VERSION ""

NS_ :

BS_:

BU_: ACU VCU
VAL_TABLE_ GEAR_FAULT 1 "GEAR_FAULT" 0 "GEAR_NO_FAULT" ;
VAL_TABLE_ GEAR_Act 2 "GEAR_ACTUAL_REVERSE" 1 "GEAR_ACTUAL_DRIVE" 0 "GEAR_ACTUAL_NEUTRAL" ;
VAL_TABLE_ GEAR_TARGET 2 "GEAR_TARGET_REVERSE" 1 "GEAR_TARGET_DRIVE" 0 "GEAR_TARGET_NEUTRAL" ;
VAL_TABLE_ GEAR_EN_CTRL 1 "GEAR_EN_CTRL_ENABLE" 0 "GEAR_EN_CTRL_DISABLE" ;
VAL_TABLE_ BRAKE_COM_FAULT 1 "BRAKE_COM_FAULT" 0 "BRAKE_COM_NO_FAULT" ;
VAL_TABLE_ BRAKE_HW_FAULT 1 "BRAKE_SYSTEM_HW_FAULT" 0 "BRAKE_SYSTEM_HW_NO_FAULT" ;
VAL_TABLE_ AEB_EN_CTRL 1 "AEB_EN_CTRL_ENABLE" 0 "AEB_EN_CTRL_DISABLE" ;
VAL_TABLE_ BRAKE_EN_CTRL 1 "BRAKE_EN_CTRL_ENABLE" 0 "BRAKE_EN_CTRL_DISABLE" ;
VAL_TABLE_ THROTTLE_EN_CTRL 1 "DRIVE_EN_CTRL_ENABLE" 0 "DRIVE_EN_CTRL_DISABLE" ;
VAL_TABLE_ THROTTLE_EN_STATE 3 "THROTTLE_EN_STATE_STANDBY" 2 "THROTTLE_EN_STATE_TAKEOVER" 1 "THROTTLE_EN_STATE_AUTO" 0 "THROTTLE_EN_STATE_MANUAL" ;
VAL_TABLE_ THROTTLE_HW_FAULT 1 "DRIVE_SYSTEM_HW_FAULT" 0 "DRIVE_SYSTEM_HW_NO_FAULT" ;
VAL_TABLE_ THROTTLE_COM_FAULT 1 "THROTTLE_COM_FAULT" 0 "THROTTLE_COM_NO_FAULT" ;
VAL_TABLE_ STEER_EN_CTRL 1 "STEER_EN_CTRL_ENABLE" 0 "STEER_EN_CTRL_DISABLE" ;
VAL_TABLE_ STEER_COM_FAULT 1 "STEER_COM_FAULT" 0 "STEER_COM_NO_FAULT" ;
VAL_TABLE_ STEER_HW_FAULT 1 "STEER_SYSTEM_HW_FAULT" 0 "STEER_SYSTEM_HW_NO_FAULT" ;
VAL_TABLE_ STEER_EN_STATE 3 "STEER_EN_STATE_STANDBY" 2 "STEER_EN_STATE_TAKEOVER" 1 "STEER_EN_STATE_AUTO" 0 "STEER_EN_STATE_MANUAL" ;

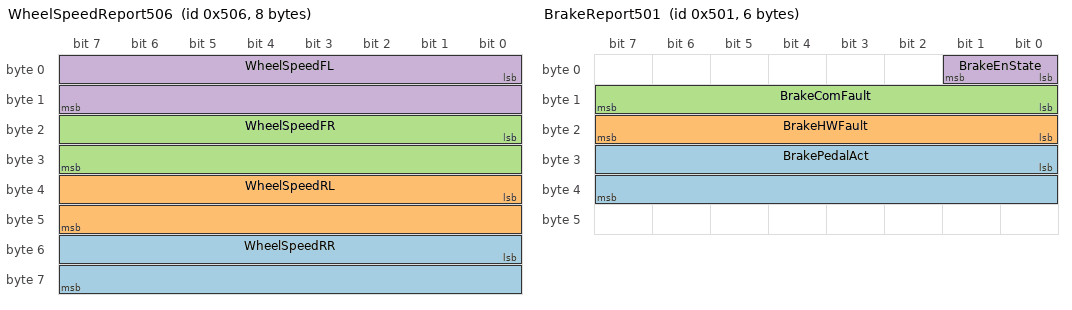
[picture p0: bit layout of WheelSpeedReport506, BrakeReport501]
BO_ 1286 WheelSpeedReport506: 8 VCU
 SG_ WheelSpeedRR : 48|16@1+ (0.001,0) [0|65.535] "m/s" Vector__XXX
 SG_ WheelSpeedRL : 32|16@1+ (0.001,0) [0|65.535] "m/s" Vector__XXX
 SG_ WheelSpeedFR : 16|16@1+ (0.001,0) [0|65.535] "m/s" Vector__XXX
 SG_ WheelSpeedFL : 0|16@1+ (0.001,0) [0|65.535] "m/s" Vector__XXX

BO_ 1285 VCUReport505: 4 VCU
 SG_ VehicleSpeed : 16|16@1+ (0.001,0) [0|65.535] "m/s" Vector__XXX
 SG_ Acc_X : 0|12@1- (0.01,0) [-10|10] "m/s^2" Vector__XXX

BO_ 1283 GearReport503: 1 VCU
 SG_ GearStateFault : 0|1@1+ (1,0) [0|1] "" Vector__XXX
 SG_ Gear_StateAct : 1|3@1+ (1,0) [0|3] "" Vector__XXX

BO_ 259 GearCommand103: 1 ACU
 SG_ GearTarget : 1|3@1+ (1,0) [0|3] "" Vector__XXX
 SG_ GearEnCtrl : 0|1@1+ (1,0) [0|1] "" Vector__XXX

BO_ 1281 BrakeReport501: 6 VCU
 SG_ BrakePedalAct : 24|16@1+ (0.1,0) [0|100] "%" Vector__XXX
 SG_ BrakeHWFault : 16|8@1+ (1,0) [0|1] "" Vector__XXX
 SG_ BrakeComFault : 8|8@1+ (1,0) [0|1] "" Vector__XXX
 SG_ BrakeEnState : 0|2@1+ (1,0) [0|3] "" Vector__XXX

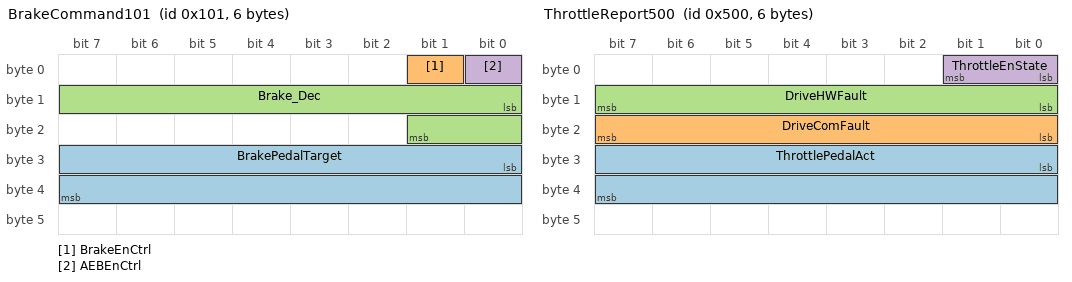
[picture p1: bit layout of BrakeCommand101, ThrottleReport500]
BO_ 257 BrakeCommand101: 6 ACU
 SG_ BrakePedalTarget : 24|16@1+ (0.1,0) [0|100] "%" Vector__XXX
 SG_ BrakeEnCtrl : 1|1@1+ (1,0) [0|1] "" Vector__XXX
 SG_ Brake_Dec : 8|10@1+ (0.01,0) [0|10.23] "m/s^2" Vector__XXX
 SG_ AEBEnCtrl : 0|1@1+ (1,0) [0|1] "" Vector__XXX

BO_ 1280 ThrottleReport500: 6 VCU
 SG_ ThrottlePedalAct : 24|16@1+ (0.1,0) [0|100] "%" Vector__XXX
 SG_ DriveComFault : 16|8@1+ (1,0) [0|1] "" Vector__XXX
 SG_ DriveHWFault : 8|8@1+ (1,0) [0|1] "" Vector__XXX
 SG_ ThrottleEnState : 0|2@1+ (1,0) [0|3] "" Vector__XXX

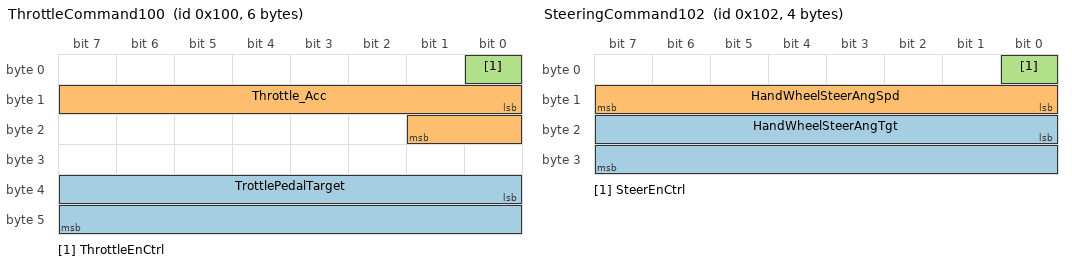
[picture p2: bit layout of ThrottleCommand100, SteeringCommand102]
BO_ 256 ThrottleCommand100: 6 ACU
 SG_ TrottlePedalTarget : 32|16@1+ (0.1,0) [0|100] "%" Vector__XXX
 SG_ Throttle_Acc : 8|10@1+ (0.01,0) [0|10.23] "m/s^2" Vector__XXX
 SG_ ThrottleEnCtrl : 0|1@1+ (1,0) [0|1] "" Vector__XXX

BO_ 258 SteeringCommand102: 4 ACU
 SG_ HandWheelSteerAngTgt : 16|16@1- (1,0) [-500|500] "deg" Vector__XXX
 SG_ HandWheelSteerAngSpd : 8|8@1+ (1,0) [0|255] "deg/s" Vector__XXX
 SG_ SteerEnCtrl : 0|1@1+ (1,0) [0|1] "" Vector__XXX

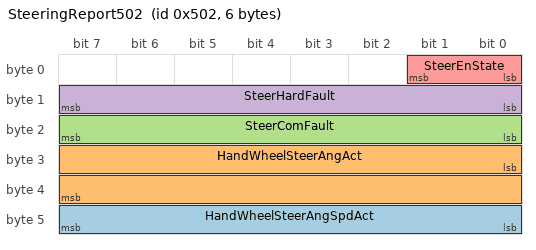
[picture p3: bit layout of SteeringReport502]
BO_ 1282 SteeringReport502: 6 VCU
 SG_ HandWheelSteerAngSpdAct : 40|8@1+ (1,0) [0|255] "deg/s" Vector__XXX
 SG_ HandWheelSteerAngAct : 24|16@1- (1,0) [-512|511] "deg" Vector__XXX
 SG_ SteerComFault : 16|8@1+ (1,0) [0|255] "" Vector__XXX
 SG_ SteerHardFault : 8|8@1+ (1,0) [0|255] "" Vector__XXX
 SG_ SteerEnState : 0|2@1- (1,0) [0|3] "" Vector__XXX

CM_ SG_ 1286 WheelSpeedRR "WheelSpeedRR";
CM_ SG_ 1286 WheelSpeedRL "WheelSpeedRL";
CM_ SG_ 1286 WheelSpeedFR "WheelSpeedFR";
CM_ SG_ 1286 WheelSpeedFL "WheelSpeedFL";
CM_ SG_ 1282 HandWheelSteerAngSpdAct "greater than 0 accel less than 0 deaccel";
CM_ SG_ 1282 HandWheelSteerAngAct "greater than 0 left less than 0 left";
BA_DEF_ SG_  "GenSigSendType" ENUM  "Cyclic";
BA_DEF_ BO_  "GenMsgSendType" ENUM  "cycle";
BA_DEF_  "BusType" STRING ;
BA_DEF_DEF_  "GenSigSendType" "Cyclic";
BA_DEF_DEF_  "GenMsgSendType" "cycle";
BA_DEF_DEF_  "BusType" "CAN";
VAL_ 1283 GearStateFault 1 "GEAR_FAULT" 0 "GEAR_NO_FAULT" ;
VAL_ 1283 Gear_StateAct 2 "GEAR_ACTUAL_REVERSE" 1 "GEAR_ACTUAL_DRIVE" 0 "GEAR_ACTUAL_NEUTRAL" ;
VAL_ 259 GearTarget 2 "GEAR_TARGET_REVERSE" 1 "GEAR_TARGET_DRIVE" 0 "GEAR_TARGET_PARK" ;
VAL_ 259 GearEnCtrl 1 "GEAR_EN_CTRL_ENABLE" 0 "GEAR_EN_CTRL_DISABLE" ;
VAL_ 1281 BrakeHWFault 1 "BRAKE_SYSTEM_HW_FAULT" 0 "BRAKE_SYSTEM_HW_NO_FAULT" ;
VAL_ 1281 BrakeComFault 1 "BRAKE_COM_FAULT" 0 "BRAKE_COM_NO_FAULT" ;
VAL_ 257 BrakeEnCtrl 1 "BRAKE_EN_CTRL_ENABLE" 0 "BRAKE_EN_CTRL_DISABLE" ;
VAL_ 257 AEBEnCtrl 1 "AEB_EN_CTRL_ENABLE" 0 "AEB_EN_CTRL_DISABLE" ;
VAL_ 1280 DriveComFault 1 "THROTTLE_COM_FAULT" 0 "THROTTLE_COM_NO_FAULT" ;
VAL_ 1280 DriveHWFault 1 "DRIVE_SYSTEM_HW_FAULT" 0 "DRIVE_SYSTEM_HW_NO_FAULT" ;
VAL_ 1280 ThrottleEnState 3 "THROTTLE_EN_STATE_STANDBY" 2 "THROTTLE_EN_STATE_TAKEOVER" 1 "THROTTLE_EN_STATE_AUTO" 0 "THROTTLE_EN_STATE_MANUAL" ;
VAL_ 256 ThrottleEnCtrl 1 "DRIVE_EN_CTRL_ENABLE" 0 "DRIVE_EN_CTRL_DISABLE" ;
VAL_ 258 SteerEnCtrl 1 "SteerEnCtrlEnable" 0 "SteerEnCtrlDisable" ;
VAL_ 1282 SteerComFault 1 "SteerComFault" 0 "SteerComNoFault" ;
VAL_ 1282 SteerHardFault 1 "SteerSystemHwFault" 0 "SteerSystemHwNoFault" ;
VAL_ 1282 SteerEnState 3 "SteerEnStateStandby" 2 "SteerEnStateTakeover" 1 "SteerEnStateAuto" 0 "SteerEnStateManual" ;
